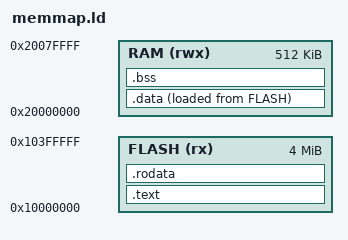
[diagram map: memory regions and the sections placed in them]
MEMORY
{
    FLASH (rx)  : ORIGIN = 0x10000000, LENGTH = 4M
    RAM (rwx)   : ORIGIN = 0x20000000, LENGTH = 512K
}

ENTRY(_start)

SECTIONS
{
    .text : {
        KEEP(*(.MBR))
        *(.text*)
        . = ALIGN(4);
    } > FLASH

    .rodata : {
        *(.rodata*)
        *(.srodata*)
        . = ALIGN(4);
    } > FLASH

    .data : {
        __data_start = .;
        *(.data*)
        *(.sdata*)
        . = ALIGN(4);
        __data_end = .;
    } > RAM AT > FLASH
    __data_load = LOADADDR(.data);

    .bss (NOLOAD) : {
        . = ALIGN(4);
        __bss_start = .;
        *(.bss*)
        *(.sbss*)
        *(COMMON)
        . = ALIGN(4);
        __bss_end = .;
    } > RAM

    __stack_top = ORIGIN(RAM) + LENGTH(RAM);
}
